AUTOSAR XML (schema 00049)
package /ota/software_componenets
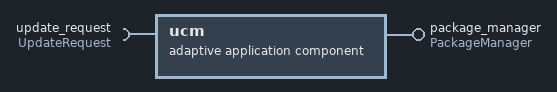
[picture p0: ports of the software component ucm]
  adaptive application sw component type ucm
    provide port package_manager: provided-interface=PackageManager
    require port update_request: required-interface=UpdateRequest
  adaptive application sw component type ota
    require port package_manager: required-interface=PackageManager
  adaptive application sw component type sm
    provide port update_request: provided-interface=UpdateRequest
  adaptive application sw component type Car_GUI
    provide port car_control: provided-interface=CarControl
